# STM32H743 register map
File version: 2.4
CPU: CM7 r0p1, little endian, MPU, FPU, 4 interrupt priority bits
Registers are 32-bit, read-write, reset 0x0 unless marked. A register's access mark holds for its fields unless they carry their own. Offsets are from the block's base; [hi:lo] are bit positions; {n}, {i} and the like mark numbered series.

## Ethernet_MTL — 以太网：MTL 模式寄存器（MTL）
Base 0x40028C00
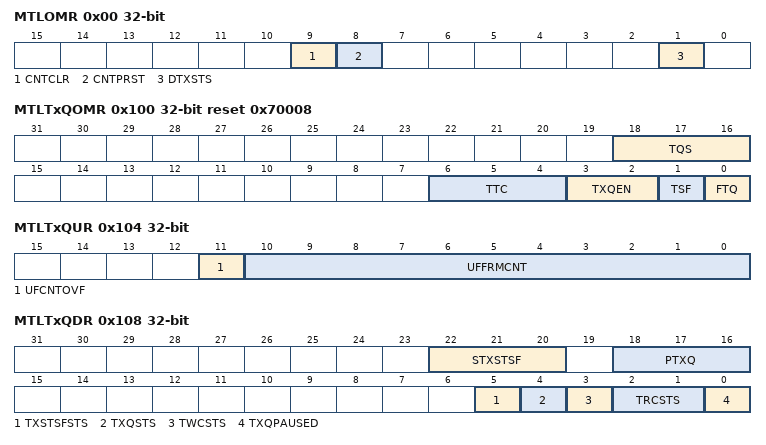
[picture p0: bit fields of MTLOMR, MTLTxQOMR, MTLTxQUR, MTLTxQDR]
0x00 MTLOMR — 操作模式寄存器
  [9] CNTCLR — 计数器清零
  [8] CNTPRST — 计数器预置
  [1] DTXSTS — 丢弃的发送包状态
0x20 MTLISR ro — 中断状态寄存器
  [0] Q0IS — 队列中断状态
0x100 MTLTxQOMR access per field reset 0x70008 — 发送队列操作模式寄存器
  [18:16] TQS rw — 发送队列大小
  [6:4] TTC rw — 发送阈值控制
  [3:2] TXQEN ro — 发送队列使能
  [1] TSF rw — 发送存储转发
  [0] FTQ rw — 刷新发送队列
0x104 MTLTxQUR ro — 发送队列下溢寄存器
  [11] UFCNTOVF — 下溢计数器溢出标志
  [10:0] UFFRMCNT — 下溢包计数器
0x108 MTLTxQDR ro — 发送队列调试寄存器
  [22:20] STXSTSF — 存储转发占用状态
  [18:16] PTXQ — 已暂停的发送队列
  [5] TXSTSFSTS — 发送存储转发状态
  [4] TXQSTS — 发送队列状态
  [3] TWCSTS — 发送写控制器状态
  [2:1] TRCSTS — 发送读控制器状态
  [0] TXQPAUSED — 发送队列暂停状态
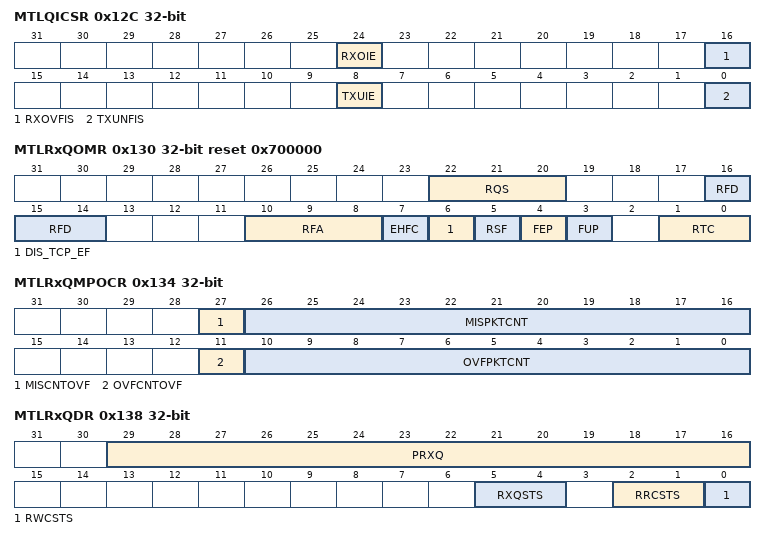
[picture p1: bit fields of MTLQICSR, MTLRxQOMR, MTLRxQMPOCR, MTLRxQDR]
0x12C MTLQICSR — 队列中断控制状态寄存器
  [24] RXOIE — 接收溢出中断使能
  [16] RXOVFIS — 接收溢出中断状态
  [8] TXUIE — 发送下溢中断使能
  [0] TXUNFIS — 发送下溢中断状态
0x130 MTLRxQOMR access per field reset 0x700000 — 接收队列操作模式寄存器
  [22:20] RQS ro — 接收队列大小
  [16:14] RFD rw — 接收流控去激活阈值
  [10:8] RFA rw — 接收流控激活阈值
  [7] EHFC rw — 使能硬件流控
  [6] DIS_TCP_EF rw — 禁止 TCP 校验和卸载错误转发
  [5] RSF rw — 接收存储转发
  [4] FEP rw — 转发错误包
  [3] FUP rw — 转发短帧
  [1:0] RTC rw — 接收阈值控制
0x134 MTLRxQMPOCR ro — 接收队列丢包和溢出计数寄存器
  [27] MISCNTOVF — 丢包计数溢出标志
  [26:16] MISPKTCNT — 丢包计数
  [11] OVFCNTOVF — 溢出计数溢出标志
  [10:0] OVFPKTCNT — 溢出包计数
0x138 MTLRxQDR ro — 接收队列调试寄存器
  [29:16] PRXQ — 已暂停的接收队列
  [5:4] RXQSTS — 接收队列状态
  [2:1] RRCSTS — 接收读控制器状态
  [0] RWCSTS — 接收写控制器状态

## HRTIM_Master — 高分辨率定时器：主定时器
Base 0x40017400
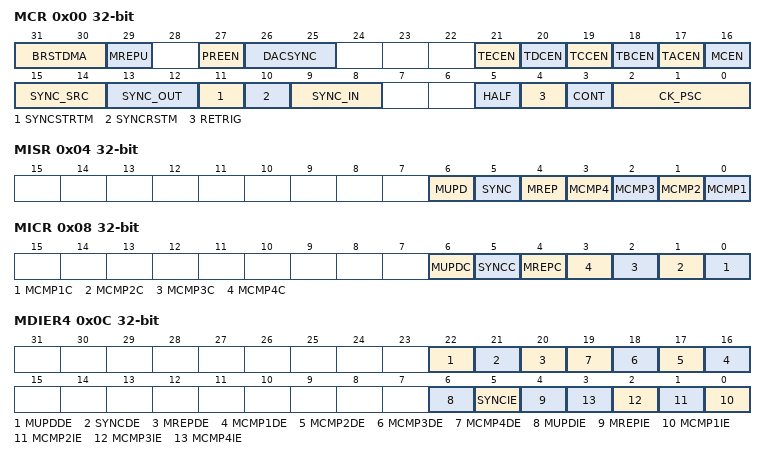
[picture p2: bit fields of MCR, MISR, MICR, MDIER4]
0x00 MCR — 主定时器控制寄存器
  [31:30] BRSTDMA — 突发 DMA 更新
  [29] MREPU — 主定时器重复更新
  [27] PREEN — 预装载使能
  [26:25] DACSYNC — DAC 同步
  [21] TECEN — 定时器 E 计数器使能
  [20] TDCEN — 定时器 D 计数器使能
  [19] TCCEN — 定时器 C 计数器使能
  [18] TBCEN — 定时器 B 计数器使能
  [17] TACEN — 定时器 A 计数器使能
  [16] MCEN — 主计数器使能
  [15:14] SYNC_SRC — 同步源
  [13:12] SYNC_OUT — 同步输出
  [11] SYNCSTRTM — 同步启动主定时器
  [10] SYNCRSTM — 同步复位主定时器
  [9:8] SYNC_IN — 同步输入
  [5] HALF — 半模式使能
  [4] RETRIG — 主定时器可重触发模式
  [3] CONT — 主定时器连续模式
  [2:0] CK_PSC — HRTIM 主时钟预分频器
0x04 MISR ro — 主定时器中断状态寄存器
  [6] MUPD — 主更新中断标志
  [5] SYNC — 同步输入中断标志
  [4] MREP — 主重复中断标志
  [n-1] MCMP{n} (n=1..4) — 主比较 {n} 中断标志
0x08 MICR wo — 主定时器中断清除寄存器
  [6] MUPDC — 主更新中断标志清除
  [5] SYNCC — 同步输入中断标志清除
  [4] MREPC — 重复中断标志清除
  [n-1] MCMP{n}C (n=1..4) — 主比较 {n} 中断标志清除
0x0C MDIER4 — 主定时器 DMA/中断使能寄存器
  [22] MUPDDE — 主更新 DMA 使能
  [21] SYNCDE — 同步 DMA 使能
  [20] MREPDE — 重复 DMA 使能
  [n+15] MCMP{n}DE (n=1..4) — 主比较 {n} DMA 使能
  [6] MUPDIE — 主更新中断使能
  [5] SYNCIE — 同步中断使能
  [4] MREPIE — 重复中断使能
  [n-1] MCMP{n}IE (n=1..4) — 主比较 {n} 中断使能
0x10 MCNTR — 主定时器计数器寄存器
  [15:0] MCNT — 计数器值
0x14 MPER reset 0xFFFF — 主定时器周期寄存器
  [15:0] MPER — 主定时器周期值
0x18 MREP — 主定时器重复寄存器
  [7:0] MREP — 主定时器重复计数值
0x1C MCMP1R — 主定时器比较 1 寄存器
  [15:0] MCMP1 — 主定时器比较 1 值
{0x1C+4i} MCMP{i}R (i=2..4) — 主定时器比较 {i} 寄存器
  [15:0] MCMP{i} — 主定时器比较 {i} 值

## DFSDM — Sigma-Delta 调制器数字滤波器
Base 0x40017000
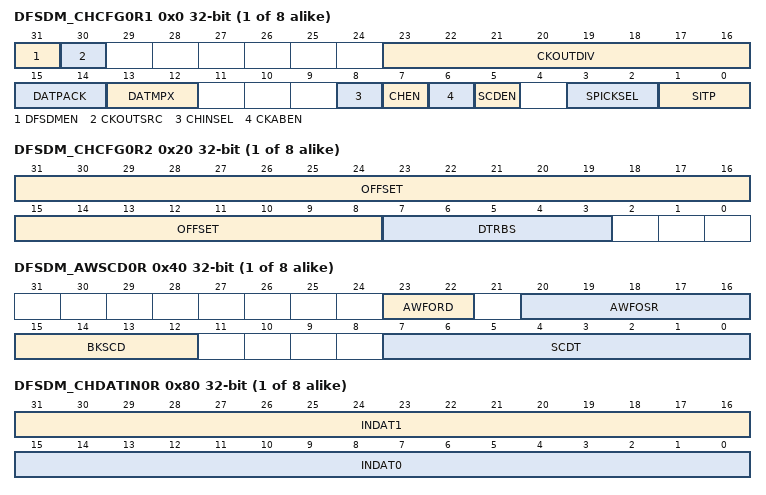
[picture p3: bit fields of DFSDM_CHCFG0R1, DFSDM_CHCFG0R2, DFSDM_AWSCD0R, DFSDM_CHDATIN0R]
{0x0+4i} DFSDM_CHCFG{i}R1 (i=0..7) — DFSDM 通道 {i} 配置寄存器 1
  [31] DFSDMEN — DFSDM 接口全局使能
  [30] CKOUTSRC — 输出串行时钟源选择
  [23:16] CKOUTDIV — 输出串行时钟分频器
  [15:14] DATPACK — DFSDM_CHDATINyR 寄存器数据打包模式
  [13:12] DATMPX — 通道 {i} 输入数据复用器
  [8] CHINSEL — 通道输入选择
  [7] CHEN — 通道 {i} 使能
  [6] CKABEN — 通道 {i} 时钟丢失检测器使能
  [5] SCDEN — 通道 {i} 短路检测器使能
  [3:2] SPICKSEL — 通道 {i} SPI 时钟选择
  [1:0] SITP — 通道 {i} 串行接口类型
{0x20+4i} DFSDM_CHCFG{i}R2 (i=0..7) — DFSDM 通道 {i} 配置寄存器 2
  [31:8] OFFSET — 通道 {i} 24 位校准偏移
  [7:3] DTRBS — 通道 {i} 数据右移位数
{0x40+4i} DFSDM_AWSCD{i}R (i=0..7) — DFSDM 模拟看门狗与短路检测器寄存器
  [23:22] AWFORD — 通道 {i} 模拟看门狗 Sinc 滤波器阶数
  [20:16] AWFOSR — 通道 {i} 模拟看门狗滤波器过采样率（抽取率）
  [15:12] BKSCD — 通道 {i} 短路检测器刹车信号分配
  [7:0] SCDT — 通道 {i} 短路检测器阈值
{0x60+4i} DFSDM_CHWDAT{i}R ro (i=0..7) — DFSDM 通道看门狗滤波器数据寄存器
  [15:0] WDATA — 输入通道 y 看门狗数据
{0x80+4i} DFSDM_CHDATIN{i}R (i=0..7) — DFSDM 通道数据输入寄存器
  [31:16] INDAT1 — 通道 {i+1} 输入数据
  [15:0] INDAT0 — 通道 {i} 输入数据
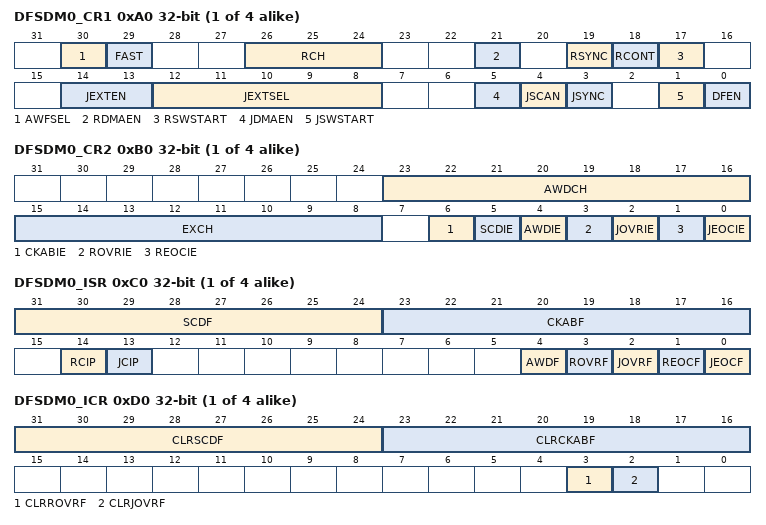
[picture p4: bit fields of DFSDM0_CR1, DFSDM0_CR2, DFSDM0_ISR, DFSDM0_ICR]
{0xA0+4i} DFSDM{i}_CR1 (i=0..3) — DFSDM 控制寄存器 1
  [30] AWFSEL — 模拟看门狗快速模式选择
  [29] FAST — 常规转换快速模式选择
  [26:24] RCH — 常规通道选择
  [21] RDMAEN — 使能 DMA 通道读取常规转换数据
  [19] RSYNC — 与 DFSDM0 同步发起常规转换
  [18] RCONT — 常规转换连续模式选择
  [17] RSWSTART — 软件启动常规通道转换
  [14:13] JEXTEN — 注入转换触发使能与触发边沿选择
  [12:8] JEXTSEL — 注入转换触发信号选择
  [5] JDMAEN — 使能 DMA 通道读取注入通道组数据
  [4] JSCAN — 注入转换扫描模式
  [3] JSYNC — 与 DFSDM0 JSWSTART 触发同步发起注入转换
  [1] JSWSTART — 启动注入通道组的转换
  [0] DFEN — DFSDM 使能
{0xB0+4i} DFSDM{i}_CR2 (i=0..3) — DFSDM 控制寄存器 2
  [23:16] AWDCH — 模拟看门狗通道选择
  [15:8] EXCH — 极值检测器通道选择
  [6] CKABIE — 时钟丢失中断使能
  [5] SCDIE — 短路检测器中断使能
  [4] AWDIE — 模拟看门狗中断使能
  [3] ROVRIE — 常规数据溢出中断使能
  [2] JOVRIE — 注入数据溢出中断使能
  [1] REOCIE — 常规转换完成中断使能
  [0] JEOCIE — 注入转换完成中断使能
{0xC0+4i} DFSDM{i}_ISR ro (i=0..3) — DFSDM 中断与状态寄存器
  [31:24] SCDF — 短路检测器标志
  [23:16] CKABF — 时钟丢失标志
  [14] RCIP — 常规转换进行中状态
  [13] JCIP — 注入转换进行中状态
  [4] AWDF — 模拟看门狗标志
  [3] ROVRF — 常规转换溢出标志
  [2] JOVRF — 注入转换溢出标志
  [1] REOCF — 常规转换完成标志
  [0] JEOCF — 注入转换完成标志
{0xD0+4i} DFSDM{i}_ICR (i=0..3) — DFSDM 中断标志清除寄存器
  [31:24] CLRSCDF — 清除短路检测器标志
  [23:16] CLRCKABF — 清除时钟丢失标志
  [3] CLRROVRF — 清除常规转换溢出标志
  [2] CLRJOVRF — 清除注入转换溢出标志
{0xE0+4i} DFSDM{i}_JCHGR (i=0..3) — DFSDM 注入通道组选择寄存器
  [7:0] JCHG — 注入通道组选择
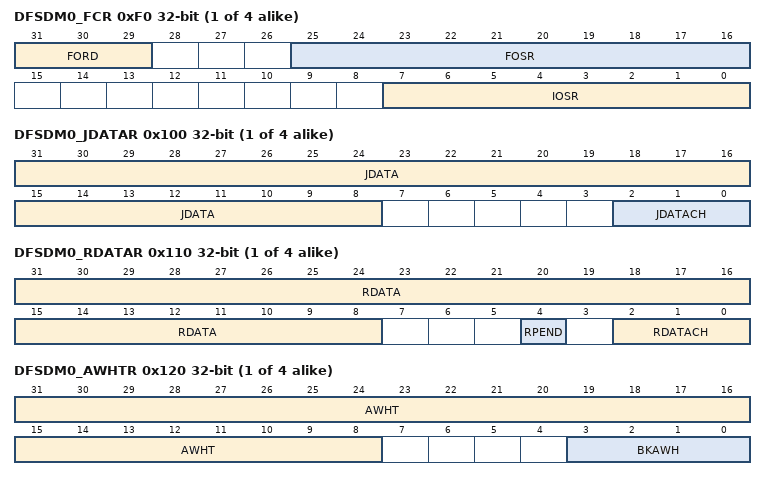
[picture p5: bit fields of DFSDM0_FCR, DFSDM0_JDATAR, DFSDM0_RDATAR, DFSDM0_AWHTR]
{0xF0+4i} DFSDM{i}_FCR (i=0..3) — DFSDM 滤波器控制寄存器
  [31:29] FORD — Sinc 滤波器阶数
  [25:16] FOSR — Sinc 滤波器过采样率（抽取率）
  [7:0] IOSR — 积分器过采样率（平均长度）
{0x100+4i} DFSDM{i}_JDATAR ro (i=0..3) — DFSDM 注入组数据寄存器
  [31:8] JDATA — 注入组转换数据
  [2:0] JDATACH — 最近完成转换的注入通道
{0x110+4i} DFSDM{i}_RDATAR ro (i=0..3) — DFSDM 常规通道数据寄存器
  [31:8] RDATA — 常规通道转换数据
  [4] RPEND — 常规通道待处理数据
  [2:0] RDATACH — 最近完成转换的常规通道
{0x120+4i} DFSDM{i}_AWHTR (i=0..3) — DFSDM 模拟看门狗高阈值寄存器
  [31:8] AWHT — 模拟看门狗高阈值
  [3:0] BKAWH — 模拟看门狗高阈值事件刹车信号分配
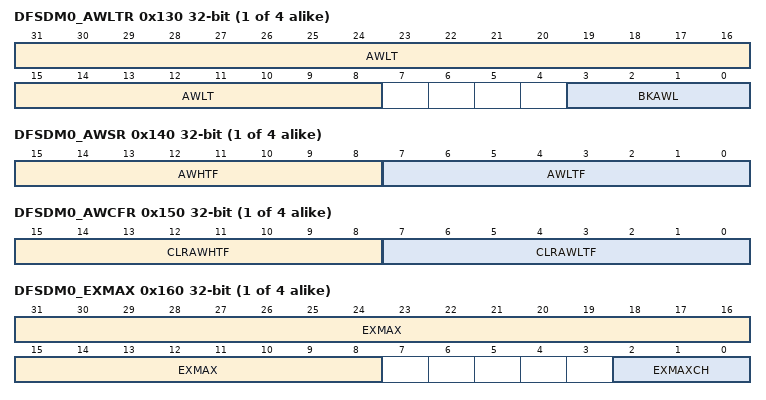
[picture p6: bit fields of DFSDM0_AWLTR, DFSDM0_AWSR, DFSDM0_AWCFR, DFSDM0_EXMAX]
{0x130+4i} DFSDM{i}_AWLTR (i=0..3) — DFSDM 模拟看门狗低阈值寄存器
  [31:8] AWLT — 模拟看门狗低阈值
  [3:0] BKAWL — 模拟看门狗低阈值事件刹车信号分配
{0x140+4i} DFSDM{i}_AWSR ro (i=0..3) — DFSDM 模拟看门狗状态寄存器
  [15:8] AWHTF — 模拟看门狗高阈值标志
  [7:0] AWLTF — 模拟看门狗低阈值标志
{0x150+4i} DFSDM{i}_AWCFR (i=0..3) — DFSDM 模拟看门狗标志清除寄存器
  [15:8] CLRAWHTF — 清除模拟看门狗高阈值标志
  [7:0] CLRAWLTF — 清除模拟看门狗低阈值标志
{0x160+4i} DFSDM{i}_EXMAX ro (i=0..3) — DFSDM 极值检测器最大值寄存器
  [31:8] EXMAX — 极值检测器最大值
  [2:0] EXMAXCH — 极值检测器最大值数据通道
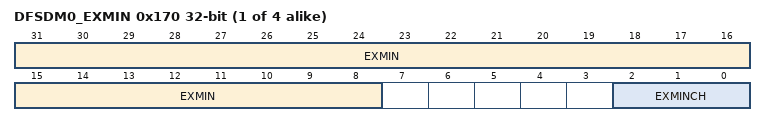
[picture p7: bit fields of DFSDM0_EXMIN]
{0x170+4i} DFSDM{i}_EXMIN ro (i=0..3) — DFSDM 极值检测器最小值寄存器
  [31:8] EXMIN — 极值检测器最小值
  [2:0] EXMINCH — 极值检测器最小值数据通道
{0x180+4i} DFSDM{i}_CNVTIMR ro (i=0..3) — DFSDM 转换定时器寄存器
  [31:4] CNVCNT — 28 位转换时间计数定时器
